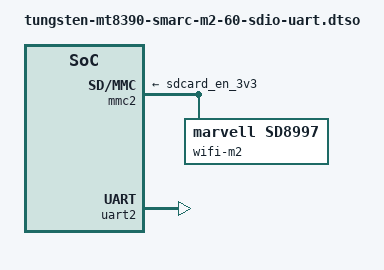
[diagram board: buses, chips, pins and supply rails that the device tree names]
// SPDX-License-Identifier: (GPL-2.0+ OR MIT)
/*
 * SDIO 60 SDIO-UART module
 */

/dts-v1/;
/plugin/;

&sdcard_en_3v3 {
	startup-delay-us = <1000>;
	off-on-delay-us = <100000>;
};

&mmc2 {
	status = "okay";
	vmmc-supply = <&sdcard_en_3v3>;

	wifi-m2 {
		compatible = "marvell,sd8997";
		fwtype = "sdio-uart";
	};
};

&uart2 {
	status = "okay";
};
